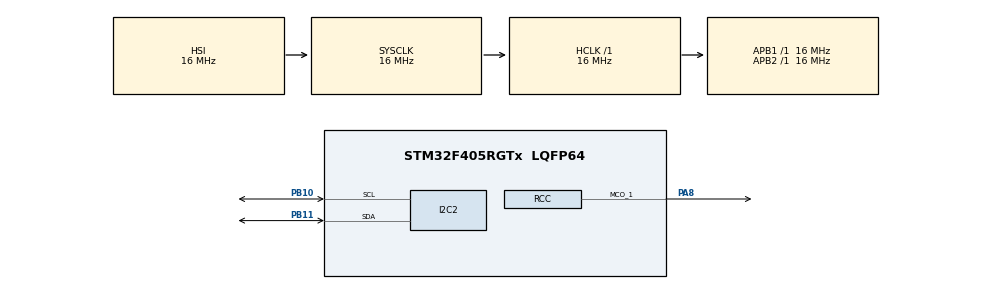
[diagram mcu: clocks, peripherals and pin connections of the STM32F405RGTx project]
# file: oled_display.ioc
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I2C2.I2C_Mode=I2C_Fast
Mcu.Family=STM32F4
Mcu.Name=STM32F405RGTx
Mcu.Package=LQFP64
NVIC.PriorityGroup=NVIC_PRIORITYGROUP_4
PA13.Mode=Serial_Wire
PA13.Signal=SYS_JTMS-SWDIO
PA14.Mode=Serial_Wire
PA14.Signal=SYS_JTCK-SWCLK
PA8.Mode=Clock-out-1
PA8.Signal=RCC_MCO_1
PB10.Mode=I2C
PB10.Signal=I2C2_SCL
PB11.Mode=I2C
PB11.Signal=I2C2_SDA
PH0-OSC_IN.Mode=HSE-External-Oscillator
PH0-OSC_IN.Signal=RCC_OSC_IN
PH1-OSC_OUT.Mode=HSE-External-Oscillator
PH1-OSC_OUT.Signal=RCC_OSC_OUT
ProjectManager.HeapSize=0x200
ProjectManager.StackSize=0x400
ProjectManager.TargetToolchain=STM32CubeIDE
RCC.AHBFreq_Value=16000000
RCC.APB1Freq_Value=16000000
RCC.APB2Freq_Value=16000000
RCC.CortexFreq_Value=16000000
RCC.HSE_VALUE=25000000
RCC.HSI_VALUE=16000000
RCC.LSE_VALUE=32768
RCC.SYSCLKFreq_VALUE=16000000
RCC.VCOOutputFreq_Value=192000000
board=custom

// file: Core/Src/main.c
/* USER CODE BEGIN Header */
/**
  ******************************************************************************
  * @file           : main.c
  * @brief          : Main program body
  ******************************************************************************
  * @attention
  *
  * Copyright (c) 2026 STMicroelectronics.
  * All rights reserved.
  *
  * This software is licensed under terms that can be found in the LICENSE file
  * in the root directory of this software component.
  * If no LICENSE file comes with this software, it is provided AS-IS.
  *
  ******************************************************************************
  */
/* USER CODE END Header */
#include "main.h"

/* USER CODE BEGIN Includes */
#include "ssd1306.h"
#include "fonts.h"
#include "stdio.h"
#include "bitmap.h"
#include "horse_anim.h"
#include <string.h>
/* USER CODE END Includes */

I2C_HandleTypeDef hi2c2;

void SystemClock_Config(void);
static void MX_GPIO_Init(void);
static void MX_I2C2_Init(void);

int main(void)
{

  /* MCU Configuration--------------------------------------------------------*/

  /* Reset of all peripherals, Initializes the Flash interface and the Systick. */
  HAL_Init();

  /* Configure the system clock */
  SystemClock_Config();

  /* Initialize all configured peripherals */
  MX_GPIO_Init();
  MX_I2C2_Init();
  /* USER CODE BEGIN 2 */
//   SSD1306_Init (); // initialise the display
//   SSD1306_GotoXY (10,10); // goto 10, 10
//   SSD1306_Puts ("HELLO", &Font_11x18, 1); // print Hello
//   SSD1306_GotoXY (10, 30);
//   SSD1306_Puts ("WORLD !!", &Font_11x18, 1);
//   SSD1306_UpdateScreen(); // update screen

//
//     int num = 123456; float flt = 123.45;
//     char bufnum[7]; char bufflt[7];
//     SSD1306_Init (); // initialise the display
//     sprintf (bufnum, "%d", num);
//     sprintf (bufflt, "%.2f", flt);
//     SSD1306_GotoXY (10,10); // goto 10, 10
//     SSD1306_Puts (bufnum, &Font_11x18, 1); // print Hello
//     SSD1306_GotoXY (10, 30);
//     SSD1306_Puts (bufflt, &Font_11x18, 1);
//     SSD1306_UpdateScreen(); // update screen

     SSD1306_Init();
     SSD1306_DrawBitmap(0, 0, apple, 128, 64, 1);
     SSD1306_UpdateScreen(); // update screen

     SSD1306_Init();
     SSD1306_DrawBitmap(0, 0, apple, 128, 64, 1);
     SSD1306_UpdateScreen(); // update screen

     SSD1306_ScrollRight(0x00, 0x07);    // scroll entire screen (Page0 to Page7) right
     HAL_Delay (5000);
     SSD1306_Stopscroll();

     SSD1306_ScrollLeft(0x00, 0x07);    // scroll entire screen (Page0 to Page7) right
     HAL_Delay (5000);
     SSD1306_Stopscroll();

  /* USER CODE END 2 */

  /* Infinite loop */
  while (1)
  {
	  //// HORSE ANIMATION START //////

	//	  SSD1306_Clear();
	//	  SSD1306_DrawBitmap(0,0,horse1,128,64,1);
	//	  SSD1306_UpdateScreen();
	//
	//	  SSD1306_Clear();
	//	  SSD1306_DrawBitmap(0,0,horse2,128,64,1);
	//	  SSD1306_UpdateScreen();
	//
	//	  SSD1306_Clear();
	//	  SSD1306_DrawBitmap(0,0,horse3,128,64,1);
	//	  SSD1306_UpdateScreen();
	//
	//	  SSD1306_Clear();
	//	  SSD1306_DrawBitmap(0,0,horse4,128,64,1);
	//	  SSD1306_UpdateScreen();
	//
	//	  SSD1306_Clear();
	//	  SSD1306_DrawBitmap(0,0,horse5,128,64,1);
	//	  SSD1306_UpdateScreen();
	//
	//	  SSD1306_Clear();
	//	  SSD1306_DrawBitmap(0,0,horse6,128,64,1);
	//	  SSD1306_UpdateScreen();
	//
	//
	//	  SSD1306_Clear();
	//	  SSD1306_DrawBitmap(0,0,horse7,128,64,1);
	//	  SSD1306_UpdateScreen();
	//
	//	  SSD1306_Clear();
	//	  SSD1306_DrawBitmap(0,0,horse8,128,64,1);
	//	  SSD1306_UpdateScreen();
	//
	//
	//	  SSD1306_Clear();
	//	  SSD1306_DrawBitmap(0,0,horse9,128,64,1);
	//	  SSD1306_UpdateScreen();
	//
	//
	//	  SSD1306_Clear();
	//	  SSD1306_DrawBitmap(0,0,horse10,128,64,1);
	//	  SSD1306_UpdateScreen();

		  //// HORSE ANIMATION ENDS //////
  }
}

void SystemClock_Config(void)
{
  RCC_OscInitTypeDef RCC_OscInitStruct = {0};
  RCC_ClkInitTypeDef RCC_ClkInitStruct = {0};

  /** Configure the main internal regulator output voltage
  */
  __HAL_RCC_PWR_CLK_ENABLE();
  __HAL_PWR_VOLTAGESCALING_CONFIG(PWR_REGULATOR_VOLTAGE_SCALE1);

  /** Initializes the RCC Oscillators according to the specified parameters
  * in the RCC_OscInitTypeDef structure.
  */
  RCC_OscInitStruct.OscillatorType = RCC_OSCILLATORTYPE_HSI;
  RCC_OscInitStruct.HSIState = RCC_HSI_ON;
  RCC_OscInitStruct.HSICalibrationValue = RCC_HSICALIBRATION_DEFAULT;
  RCC_OscInitStruct.PLL.PLLState = RCC_PLL_NONE;
  if (HAL_RCC_OscConfig(&RCC_OscInitStruct) != HAL_OK)
  {
    Error_Handler();
  }

  /** Initializes the CPU, AHB and APB buses clocks
  */
  RCC_ClkInitStruct.ClockType = RCC_CLOCKTYPE_HCLK|RCC_CLOCKTYPE_SYSCLK
                              |RCC_CLOCKTYPE_PCLK1|RCC_CLOCKTYPE_PCLK2;
  RCC_ClkInitStruct.SYSCLKSource = RCC_SYSCLKSOURCE_HSI;
  RCC_ClkInitStruct.AHBCLKDivider = RCC_SYSCLK_DIV1;
  RCC_ClkInitStruct.APB1CLKDivider = RCC_HCLK_DIV1;
  RCC_ClkInitStruct.APB2CLKDivider = RCC_HCLK_DIV1;

  if (HAL_RCC_ClockConfig(&RCC_ClkInitStruct, FLASH_LATENCY_0) != HAL_OK)
  {
    Error_Handler();
  }
  HAL_RCC_MCOConfig(RCC_MCO1, RCC_MCO1SOURCE_HSI, RCC_MCODIV_1);
}

static void MX_I2C2_Init(void)
{

  hi2c2.Instance = I2C2;
  hi2c2.Init.ClockSpeed = 400000;
  hi2c2.Init.DutyCycle = I2C_DUTYCYCLE_2;
  hi2c2.Init.OwnAddress1 = 0;
  hi2c2.Init.AddressingMode = I2C_ADDRESSINGMODE_7BIT;
  hi2c2.Init.DualAddressMode = I2C_DUALADDRESS_DISABLE;
  hi2c2.Init.OwnAddress2 = 0;
  hi2c2.Init.GeneralCallMode = I2C_GENERALCALL_DISABLE;
  hi2c2.Init.NoStretchMode = I2C_NOSTRETCH_DISABLE;
  if (HAL_I2C_Init(&hi2c2) != HAL_OK)
  {
    Error_Handler();
  }

}

static void MX_GPIO_Init(void)
{
  GPIO_InitTypeDef GPIO_InitStruct = {0};

  /* GPIO Ports Clock Enable */
  __HAL_RCC_GPIOH_CLK_ENABLE();
  __HAL_RCC_GPIOB_CLK_ENABLE();
  __HAL_RCC_GPIOA_CLK_ENABLE();

  /*Configure GPIO pin : PA8 */
  GPIO_InitStruct.Pin = GPIO_PIN_8;
  GPIO_InitStruct.Mode = GPIO_MODE_AF_PP;
  GPIO_InitStruct.Pull = GPIO_NOPULL;
  GPIO_InitStruct.Speed = GPIO_SPEED_FREQ_LOW;
  GPIO_InitStruct.Alternate = GPIO_AF0_MCO;
  HAL_GPIO_Init(GPIOA, &GPIO_InitStruct);

}

void Error_Handler(void)
{
  __disable_irq();
  while (1)
  {
  }
}
